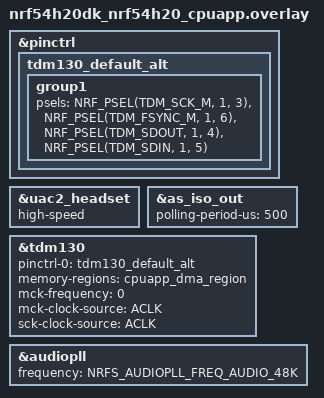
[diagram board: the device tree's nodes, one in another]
/*
 * Copyright (c) 2024 Nordic Semiconductor ASA
 *
 * SPDX-License-Identifier: Apache-2.0
 */

#include "../app.overlay"

&pinctrl {
	tdm130_default_alt: tdm130_default_alt {
		group1 {
			psels = <NRF_PSEL(TDM_SCK_M, 1, 3)>,
				<NRF_PSEL(TDM_FSYNC_M, 1, 6)>,
				<NRF_PSEL(TDM_SDOUT, 1, 4)>,
				<NRF_PSEL(TDM_SDIN, 1, 5)>;
		};
	};
};

&uac2_headset {
    /delete-property/ full-speed;
    high-speed;
};

&as_iso_out {
	polling-period-us = <500>;
};

&as_iso_out {
	polling-period-us = <500>;
};

i2s_rxtx: &tdm130 {
	status = "okay";
	pinctrl-0 = <&tdm130_default_alt>;
	pinctrl-names = "default";
	memory-regions = <&cpuapp_dma_region>;
	mck-frequency = <0>;
    mck-clock-source = "ACLK";
    sck-clock-source = "ACLK";
};

&audiopll {
    status = "okay";
    frequency = <NRFS_AUDIOPLL_FREQ_AUDIO_48K>;
};
